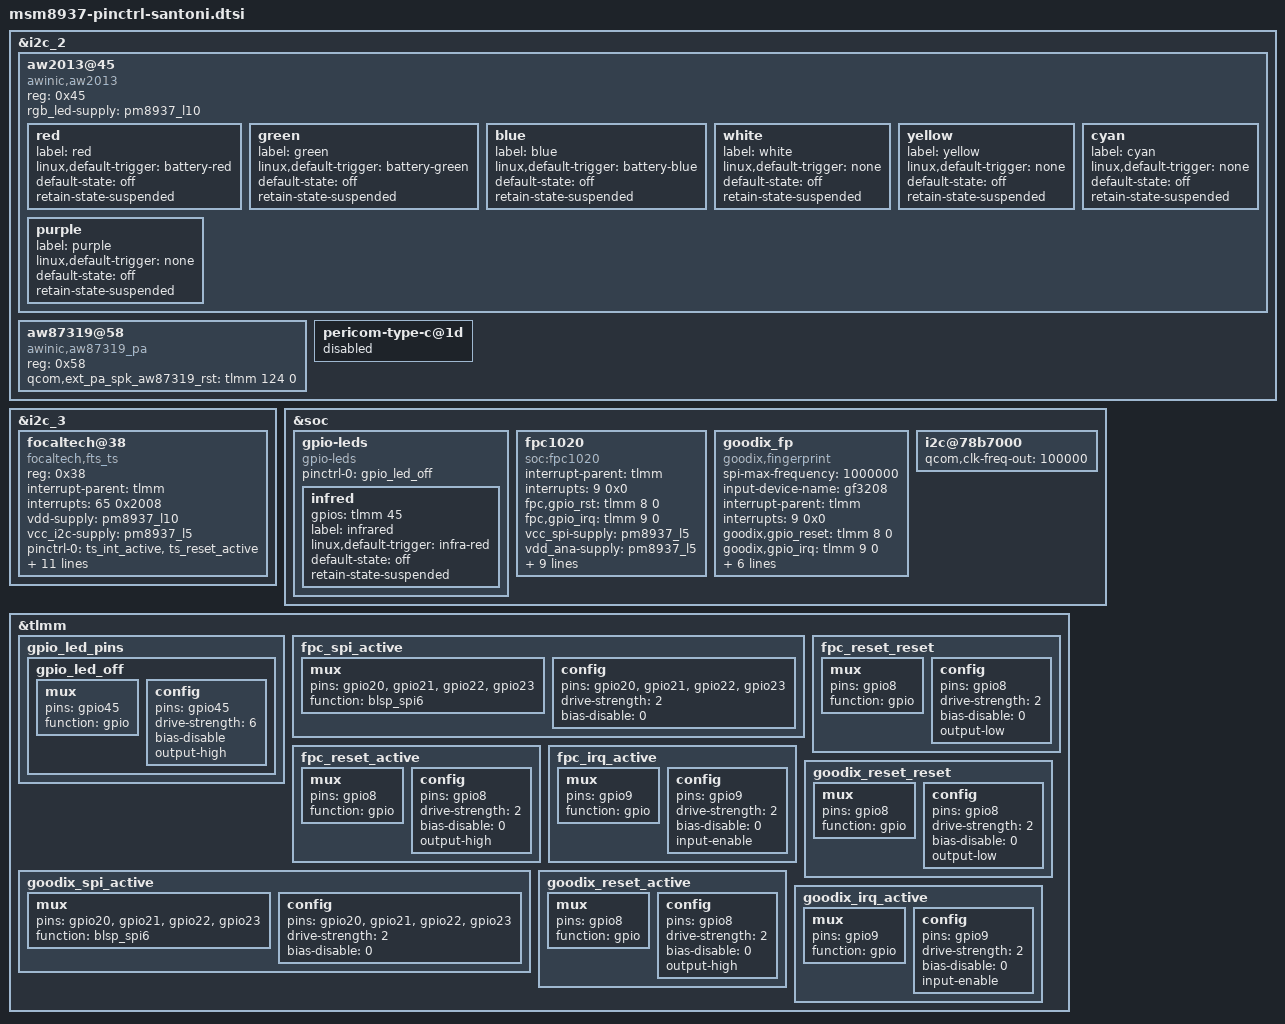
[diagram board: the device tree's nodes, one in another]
&i2c_2  {
	aw2013@45 {
		compatible = "awinic,aw2013";
		reg = <0x45>;
		rgb_led-supply = <&pm8937_l10>;

		red {
			label = "red";
			linux,default-trigger = "battery-red";
			default-state = "off";
			retain-state-suspended;
		};

		green {
			label = "green";
			linux,default-trigger = "battery-green";
			default-state = "off";
			retain-state-suspended;
		};

		blue {
			label = "blue";
			linux,default-trigger = "battery-blue";
			default-state = "off";
			retain-state-suspended;
		};

		white {
			label = "white";
			linux,default-trigger = "none";
			default-state = "off";
			retain-state-suspended;
		};

		yellow {
			label = "yellow";
			linux,default-trigger = "none";
			default-state = "off";
			retain-state-suspended;
		};

		cyan {
			label = "cyan";
			linux,default-trigger = "none";
			default-state = "off";
			retain-state-suspended;
		};

		purple {
			label = "purple";
			linux,default-trigger = "none";
			default-state = "off";
			retain-state-suspended;
		};
	};

	aw87319@58{ /*AW87319 PA*/
		compatible = "awinic,aw87319_pa";
		reg = <0x58>;
		qcom,ext_pa_spk_aw87319_rst = <&tlmm 124 0>;
	};

        pericom-type-c@1d {
                status="disabled";
        };
};

&i2c_3 {
	focaltech@38{
		compatible = "focaltech,fts_ts";
		reg = <0x38>;
		interrupt-parent = <&tlmm>;
		interrupts = <65 0x2008>;
		vdd-supply = <&pm8937_l10>;
		vcc_i2c-supply = <&pm8937_l5>;
		pinctrl-names = "pmx_ts_active","pmx_ts_suspend",
		"pmx_ts_release";
		pinctrl-0 = <&ts_int_active &ts_reset_active>;
		pinctrl-1 = <&ts_int_suspend &ts_reset_suspend>;
		pinctrl-2 = <&ts_release>;
		focaltech,reset-gpio = <&tlmm 64 0x00>;
		focaltech,irq-gpio = <&tlmm 65 0x2008>;
		focaltech,display-coords = <0 0 720 1280>;
		focaltech,max-touch-number = <10>;
		focaltech,have-key;
		focaltech,key-number = <3>;
		focaltech,keys = <139 172 158>;
		focaltech,key-y-coords = <2000 2000 2000>;
		focaltech,key-x-coords = <150 360 580>;
	};
};

&soc {
	gpio-leds {
		compatible = "gpio-leds";
		status = "okay";
		pinctrl-names = "default";
		pinctrl-0 = <&gpio_led_off>;

		infred {
			gpios = <&tlmm 45 0>;
			label = "infrared";
			linux,default-trigger = "infra-red";
			default-state = "off";
			retain-state-suspended;
		};

	};

	fpc1020 {
		compatible = "soc:fpc1020";

		interrupt-parent = <&tlmm>;
		interrupts = <9 0x0>;

		fpc,gpio_rst    = <&tlmm 8 0>;
		fpc,gpio_irq    = <&tlmm 9 0>;

		vcc_spi-supply  = <&pm8937_l5>;
		vdd_ana-supply  = <&pm8937_l5>;
		vdd_io-supply   = <&pm8937_l5>;

		fpc,enable-on-boot;
		/delete-property/ fpc,enable-wakeup;

		fpc,spi-max-frequency = <4800000>;

		clock-names = "iface_clk", "core_clk";
		clocks = <&clock_gcc clk_gcc_blsp1_ahb_clk>,
				<&clock_gcc clk_gcc_blsp1_qup1_spi_apps_clk>;

		pinctrl-names = "fpc1020_spi_active",
				"fpc1020_reset_reset",
				"fpc1020_reset_active",
				"fpc1020_irq_active";

		pinctrl-0 = <&fpc_spi_active>;
		pinctrl-1 = <&fpc_reset_reset>;
		pinctrl-2 = <&fpc_reset_active>;
		pinctrl-3 = <&fpc_irq_active>;
	};

	goodix_fp {
		compatible = "goodix,fingerprint";
		spi-max-frequency = <1000000>;
		input-device-name = "gf3208";
		interrupt-parent = <&tlmm>;
		interrupts = <9 0x0>;

		goodix,gpio_reset    = <&tlmm 8 0>;
		goodix,gpio_irq      = <&tlmm 9 0>;

		clock-names = "iface_clk", "core_clk";
		clocks = <&clock_gcc clk_gcc_blsp1_ahb_clk>,
				<&clock_gcc clk_gcc_blsp1_qup1_spi_apps_clk>;

		pinctrl-names = "goodixfp_spi_active",
				"goodixfp_reset_reset",
				"goodixfp_reset_active",
				"goodixfp_irq_active";

		pinctrl-0 = <&goodix_spi_active>;
		pinctrl-1 = <&goodix_reset_reset>;
		pinctrl-2 = <&goodix_reset_active>;
		pinctrl-3 = <&goodix_irq_active>;
	};

	i2c@78b7000 {
		qcom,clk-freq-out = <100000>;
		status = "okay";
	};
};

&tlmm {
	gpio_led_pins {
		gpio_led_off: gpio_led_off {
			mux {
				pins = "gpio45";
				function = "gpio";
			};

			config {
				pins = "gpio45";
				drive-strength = <6>;
				bias-disable;
				output-high;
			};
		};
	};

	fpc_spi_active: fpc_spi_active {
		mux {
			pins = "gpio20", "gpio21", "gpio22", "gpio23";
			function = "blsp_spi6";
		};

		config {
			pins = "gpio20", "gpio21", "gpio22", "gpio23";
			drive-strength = <2>;
			bias-disable = <0>;
		};
	};

	fpc_reset_reset: fpc_reset_reset {
		mux {
			pins = "gpio8";
			function = "gpio";
		};

		config {
			pins = "gpio8";
			drive-strength = <2>;
			bias-disable = <0>;
			output-low;
		};
	};

	fpc_reset_active: fpc_reset_active {
		mux {
			pins = "gpio8";
			function = "gpio";
		};

		config {
			pins = "gpio8";
			drive-strength = <2>;
			bias-disable = <0>;
			output-high;
		};
	};

	fpc_irq_active: fpc_irq_active {
		mux {
			pins = "gpio9";
			function = "gpio";
		};

		config {
			pins = "gpio9";
			drive-strength = <2>;
			bias-disable = <0>;
			input-enable;
		};
	};

	goodix_spi_active: goodix_spi_active {
		mux {
			pins = "gpio20", "gpio21", "gpio22", "gpio23";
			function = "blsp_spi6";
		};

		config {
			pins = "gpio20", "gpio21", "gpio22", "gpio23";
			drive-strength = <2>;
			bias-disable = <0>;
		};
	};

	goodix_reset_reset: goodix_reset_reset {
		mux {
			pins = "gpio8";
			function = "gpio";
		};

		config {
			pins = "gpio8";
			drive-strength = <2>;
			bias-disable = <0>;
			output-low;
		};
	};

	goodix_reset_active: goodix_reset_active {
		mux {
			pins = "gpio8";
			function = "gpio";
		};

		config {
			pins = "gpio8";
			drive-strength = <2>;
			bias-disable = <0>;
			output-high;
		};
	};

	goodix_irq_active: goodix_irq_active {
		mux {
			pins = "gpio9";
			function = "gpio";
		};

		config {
			pins = "gpio9";
			drive-strength = <2>;
			bias-disable = <0>;
			input-enable;
		};
	};
};
